# ES32F36xx register map
File version: 1.0
Registers are 32-bit, read-write, reset 0x0 unless marked. A register's access mark holds for its fields unless they carry their own. Offsets are from the block's base; [hi:lo] are bit positions; {n}, {i} and the like mark numbered series; 'fields as' and 'values as' point back to an identical list.

## GPIOA
Base 0x40084000
Same registers: GPIOB 0x40084040, GPIOC 0x40084080, GPIOD 0x400840C0, GPIOE 0x40084100, GPIOF 0x40084140, GPIOG 0x40084180, GPIOH 0x400841C0
0x00 DIN read
  [15:0] DIN
0x04 DOUT
  [15:0] DOUT
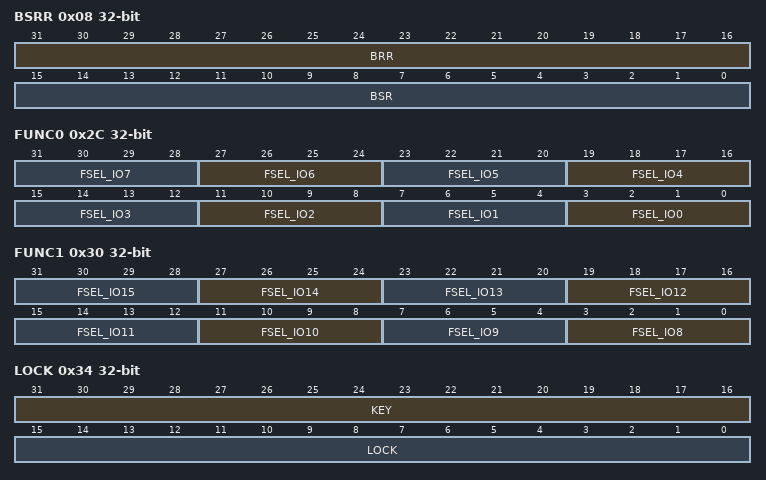
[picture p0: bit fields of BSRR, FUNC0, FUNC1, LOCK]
0x08 BSRR write
  [31:16] BRR, [15:0] BSR
0x0C BIR write
  [15:0] BIR
0x10 MODE
0x14 ODOS
0x18 PUPD
0x1C PODRV reset 0xAAAAAAAA
0x20 NODRV reset 0xAAAAAAAA
0x24 FLT
  [15:0] FLT
0x28 TYPE
  [15:0] TYPE
0x2C FUNC0
  [4n+3:4n] FSEL_IO{n} (n=0..7)
0x30 FUNC1
  [4n-29:4n-32] FSEL_IO{n} (n=8..15)
0x34 LOCK
  [31:16] KEY write, [15:0] LOCK
0x300 EXTIRER
  [15:0] EXTIRER
0x308 EXTIFER
  [15:0] EXTIFER
0x310 EXTIEN
  [15:0] EXTIEN
0x318 EXTIFLAG read
  [15:0] EXTIFLAG
0x320 EXTISFR write1
  [15:0] EXTISFR
0x328 EXTICFR write1
  [15:0] EXTICFR
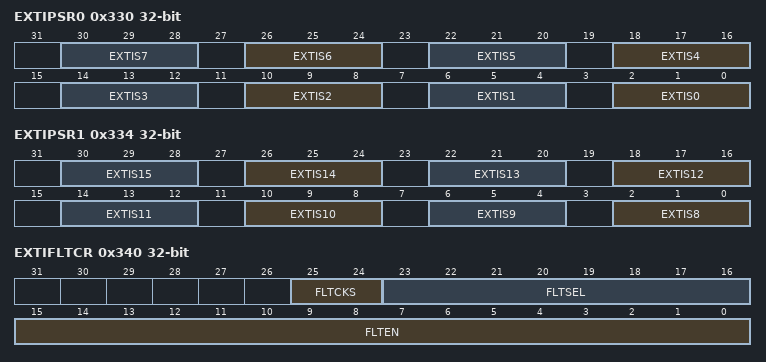
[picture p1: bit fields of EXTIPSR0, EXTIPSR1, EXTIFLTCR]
0x330 EXTIPSR0
  [4n+2:4n] EXTIS{n} (n=0..7)
0x334 EXTIPSR1
  [4n-30:4n-32] EXTIS{n} (n=8..15)
0x340 EXTIFLTCR
  [25:24] FLTCKS, [23:16] FLTSEL, [15:0] FLTEN

## AD16C4T0
Base 0x40000000
Same registers: AD16C4T1 0x40000400
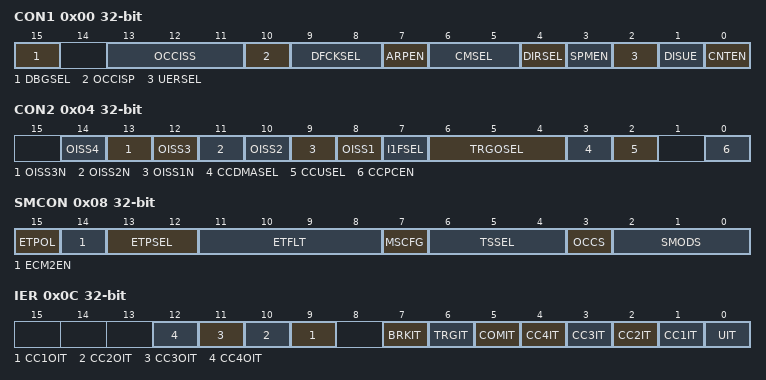
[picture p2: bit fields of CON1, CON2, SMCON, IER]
0x00 CON1
  [15] DBGSEL, [13:11] OCCISS, [10] OCCISP, [9:8] DFCKSEL, [7] ARPEN, [6:5] CMSEL, [4] DIRSEL, [3] SPMEN, [2] UERSEL, [1] DISUE, [0] CNTEN
0x04 CON2
  [2n+6] OISS{n} (n=1..4), [13] OISS3N, [11] OISS2N, [9] OISS1N, [7] I1FSEL, [6:4] TRGOSEL, [3] CCDMASEL, [2] CCUSEL, [0] CCPCEN
0x08 SMCON
  [15] ETPOL, [14] ECM2EN, [13:12] ETPSEL, [11:8] ETFLT, [7] MSCFG, [6:4] TSSEL, [3] OCCS, [2:0] SMODS
0x0C IER write
  [n+8] CC{n}OIT (n=1..4), [7] BRKIT, [6] TRGIT, [5] COMIT, [n] CC{n}IT (n=1..4), [0] UIT
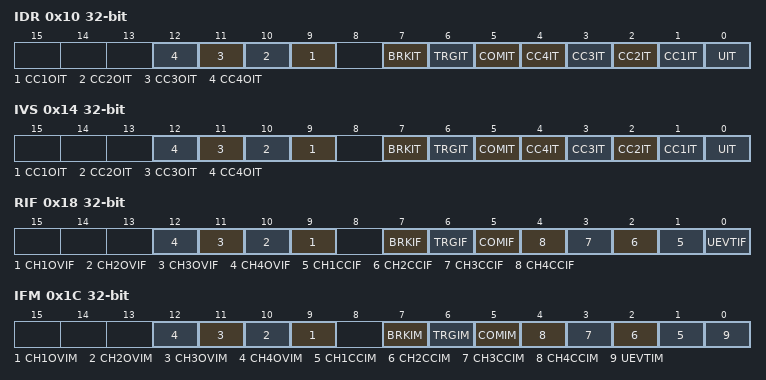
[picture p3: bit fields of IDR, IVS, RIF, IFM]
0x10 IDR write
  fields as IER
0x14 IVS read
  [n+8] CC{n}OIT write (n=1..4), [7] BRKIT, [6] TRGIT, [5] COMIT, [n] CC{n}IT (n=1..4), [0] UIT
0x18 RIF read
  [n+8] CH{n}OVIF (n=1..4), [7] BRKIF, [6] TRGIF, [5] COMIF, [n] CH{n}CCIF (n=1..4), [0] UEVTIF
0x1C IFM read
  [n+8] CH{n}OVIM (n=1..4), [7] BRKIM, [6] TRGIM, [5] COMIM, [n] CH{n}CCIM (n=1..4), [0] UEVTIM
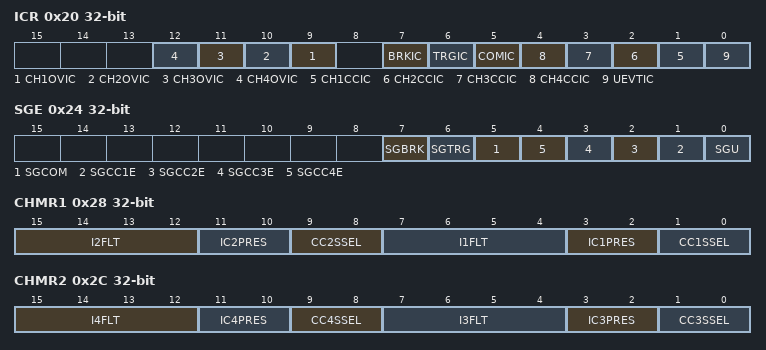
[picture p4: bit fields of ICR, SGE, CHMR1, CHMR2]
0x20 ICR clear-write1
  [n+8] CH{n}OVIC read (n=1..4), [7] BRKIC, [6] TRGIC, [5] COMIC, [n] CH{n}CCIC (n=1..4), [0] UEVTIC
0x24 SGE write
  [7] SGBRK, [6] SGTRG, [5] SGCOM, [n] SGCC{n}E (n=1..4), [0] SGU
0x28 CHMR1
  [15:12] I2FLT, [11:10] IC2PRES, [9:8] CC2SSEL, [7:4] I1FLT, [3:2] IC1PRES, [1:0] CC1SSEL
0x2C CHMR2
  [15:12] I4FLT, [11:10] IC4PRES, [9:8] CC4SSEL, [7:4] I3FLT, [3:2] IC3PRES, [1:0] CC3SSEL
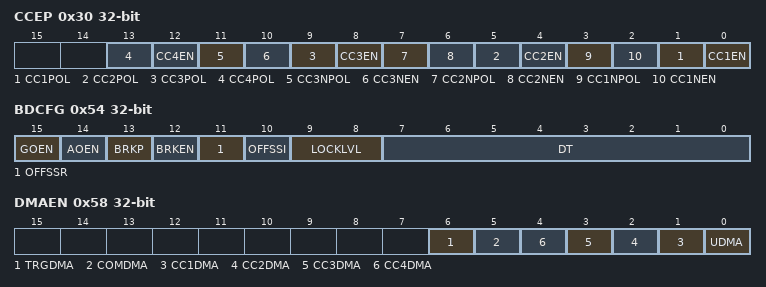
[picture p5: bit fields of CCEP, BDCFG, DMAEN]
0x30 CCEP
  [4n-3] CC{n}POL (n=1..4), [4n-4] CC{n}EN (n=1..4), [11] CC3NPOL, [10] CC3NEN, [7] CC2NPOL, [6] CC2NEN, [3] CC1NPOL, [2] CC1NEN
0x34 COUNT
  [15:0] CNTV
0x38 PRES
  [15:0] PSCV
0x3C AR
  [15:0] ARRV
0x40 REPAR
  [7:0] REPV
{0x40+4i} CCVAL{i} (i=1..4)
  [15:0] CCRV{i}
0x54 BDCFG
  [15] GOEN, [14] AOEN, [13] BRKP, [12] BRKEN, [11] OFFSSR, [10] OFFSSI, [9:8] LOCKLVL, [7:0] DT
0x58 DMAEN
  [6] TRGDMA, [5] COMDMA, [n] CC{n}DMA (n=1..4), [0] UDMA

## GP32C4T0
Base 0x40000800
Same registers: GP32C4T1 0x40000C00
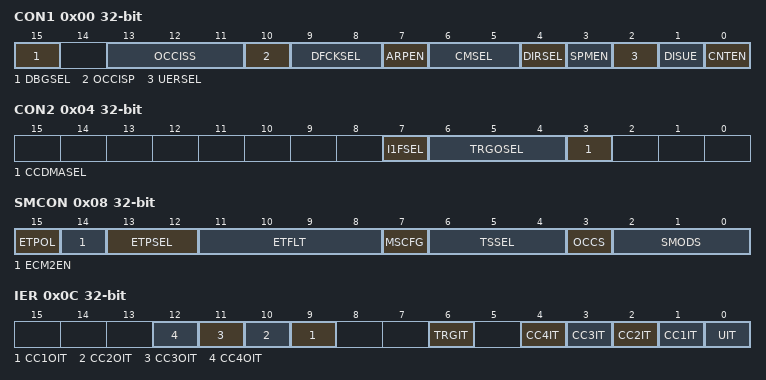
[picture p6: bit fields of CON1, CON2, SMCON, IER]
0x00 CON1
  [15] DBGSEL, [13:11] OCCISS, [10] OCCISP, [9:8] DFCKSEL, [7] ARPEN, [6:5] CMSEL, [4] DIRSEL, [3] SPMEN, [2] UERSEL, [1] DISUE, [0] CNTEN
0x04 CON2
  [7] I1FSEL, [6:4] TRGOSEL, [3] CCDMASEL
0x08 SMCON
  [15] ETPOL, [14] ECM2EN, [13:12] ETPSEL, [11:8] ETFLT, [7] MSCFG, [6:4] TSSEL, [3] OCCS, [2:0] SMODS
0x0C IER write
  [n+8] CC{n}OIT (n=1..4), [6] TRGIT, [n] CC{n}IT (n=1..4), [0] UIT
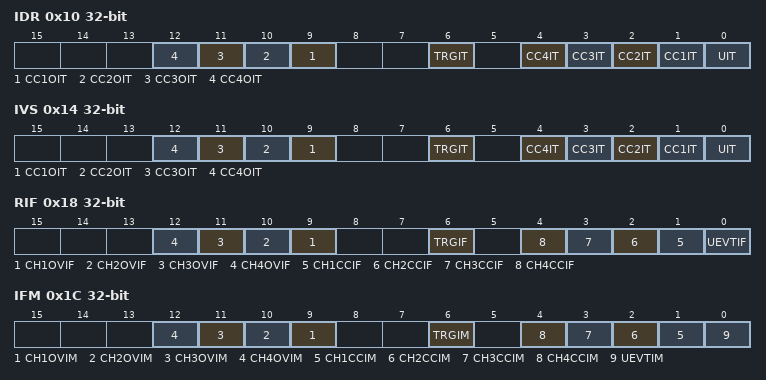
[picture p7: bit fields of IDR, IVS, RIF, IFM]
0x10 IDR write
  [n+8] CC{n}OIT (n=1..4), [6] TRGIT, [n] CC{n}IT (n=1..4), [0] UIT
0x14 IVS read
  [n+8] CC{n}OIT write (n=1..4), [6] TRGIT, [n] CC{n}IT (n=1..4), [0] UIT
0x18 RIF read
  [n+8] CH{n}OVIF (n=1..4), [6] TRGIF, [n] CH{n}CCIF (n=1..4), [0] UEVTIF
0x1C IFM read
  [n+8] CH{n}OVIM (n=1..4), [6] TRGIM, [n] CH{n}CCIM (n=1..4), [0] UEVTIM
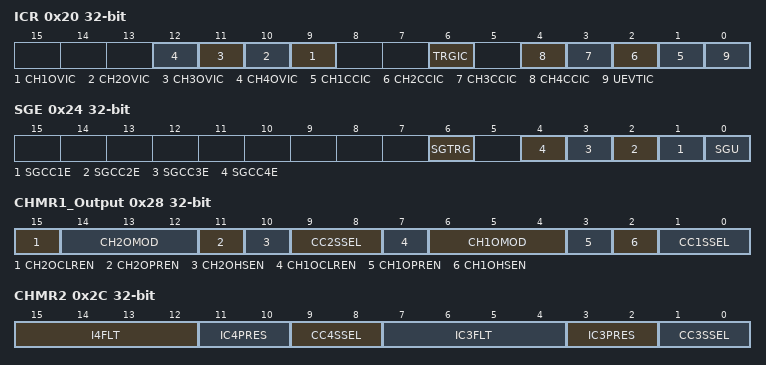
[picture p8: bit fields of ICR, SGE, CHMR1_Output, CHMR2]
0x20 ICR clear-write1
  [n+8] CH{n}OVIC read (n=1..4), [6] TRGIC, [n] CH{n}CCIC (n=1..4), [0] UEVTIC
0x24 SGE write
  [6] SGTRG, [n] SGCC{n}E (n=1..4), [0] SGU
0x28 CHMR1_Output
  [15] CH2OCLREN, [14:12] CH2OMOD, [11] CH2OPREN, [10] CH2OHSEN, [9:8] CC2SSEL, [7] CH1OCLREN, [6:4] CH1OMOD, [3] CH1OPREN, [2] CH1OHSEN, [1:0] CC1SSEL
0x2C CHMR2
  [15:12] I4FLT, [11:10] IC4PRES, [9:8] CC4SSEL, [7:4] IC3FLT, [3:2] IC3PRES, [1:0] CC3SSEL
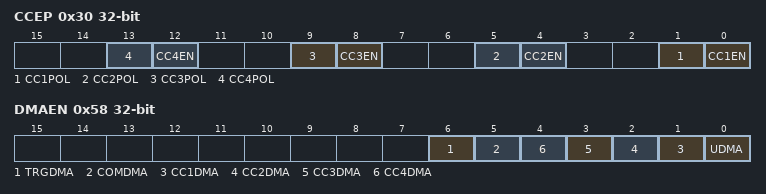
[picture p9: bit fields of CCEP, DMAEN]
0x30 CCEP
  [4n-3] CC{n}POL (n=1..4), [4n-4] CC{n}EN (n=1..4)
0x34 COUNT
  [31:0] CNTV
0x38 PRES
  [15:0] PSCV
0x3C AR reset 0xFFFFFFFF
  [31:0] ARRV
{0x40+4i} CCVAL{i} (i=1..4)
  [31:0] CCRV{i}
0x58 DMAEN
  [6] TRGDMA, [5] COMDMA, [n] CC{n}DMA (n=1..4), [0] UDMA

## GP16C4T0
Base 0x40001800
Same registers: GP16C4T1 0x40001C00
Registers as GP32C4T0, without CHMR1_Output; these are added or differ:
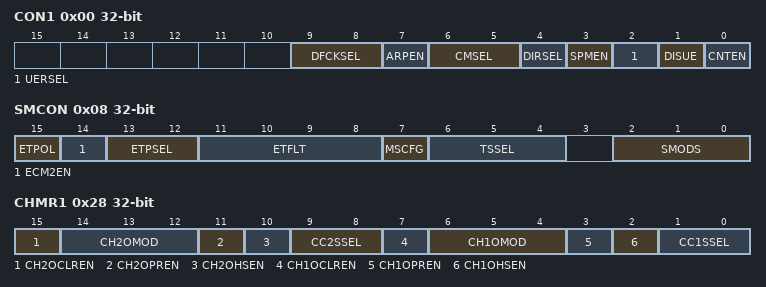
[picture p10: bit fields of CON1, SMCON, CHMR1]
0x00 CON1
  [9:8] DFCKSEL, [7] ARPEN, [6:5] CMSEL, [4] DIRSEL, [3] SPMEN, [2] UERSEL, [1] DISUE, [0] CNTEN
0x08 SMCON
  [15] ETPOL, [14] ECM2EN, [13:12] ETPSEL, [11:8] ETFLT, [7] MSCFG, [6:4] TSSEL, [2:0] SMODS
0x28 CHMR1
  [15] CH2OCLREN, [14:12] CH2OMOD, [11] CH2OPREN, [10] CH2OHSEN, [9:8] CC2SSEL, [7] CH1OCLREN, [6:4] CH1OMOD, [3] CH1OPREN, [2] CH1OHSEN, [1:0] CC1SSEL
0x34 COUNT
  [15:0] CNTV
0x3C AR reset 0xFFFF
  [15:0] ARRV
{0x40+4i} CCVAL{i} (i=1..4)
  [15:0] CCRV{i}
